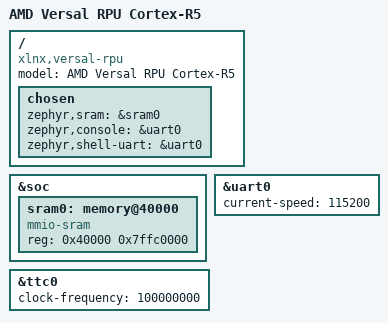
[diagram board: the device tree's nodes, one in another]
/*
 * Copyright (c) 2026, Advanced Micro Devices, Inc.
 *
 * SPDX-License-Identifier: Apache-2.0
 */

/dts-v1/;
#include <arm/xilinx/versal_rpu.dtsi>

/ {
	model = "AMD Versal RPU Cortex-R5";
	compatible = "xlnx,versal-rpu";

	chosen {
		zephyr,sram = &sram0;
		zephyr,console = &uart0;
		zephyr,shell-uart = &uart0;
	};
};

&soc {
	sram0: memory@40000 {
		compatible = "mmio-sram";
		reg = <0x40000 0x7ffc0000>;
	};
};

&uart0 {
	status = "okay";
	current-speed = <115200>;
};

&ttc0 {
	status = "okay";
	clock-frequency = <100000000>;
};
